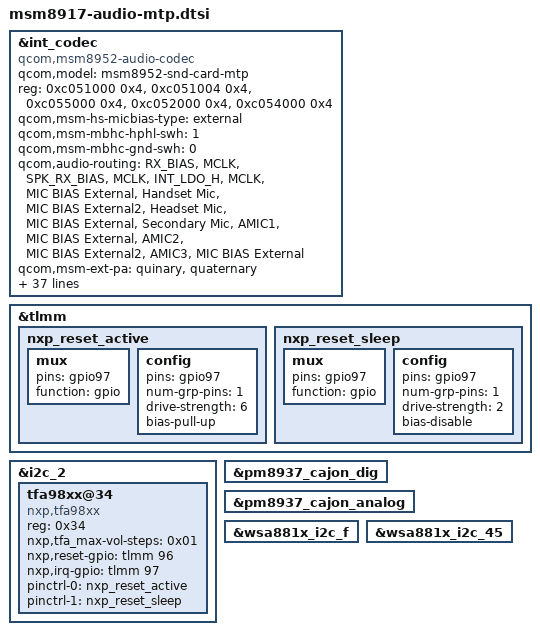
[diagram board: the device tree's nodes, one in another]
/*
 * Copyright (c) 2015-2016, The Linux Foundation. All rights reserved.
 *
 * This program is free software; you can redistribute it and/or modify
 * it under the terms of the GNU General Public License version 2 and
 * only version 2 as published by the Free Software Foundation.
 *
 * This program is distributed in the hope that it will be useful,
 * but WITHOUT ANY WARRANTY; without even the implied warranty of
 * MERCHANTABILITY or FITNESS FOR A PARTICULAR PURPOSE.  See the
 * GNU General Public License for more details.
 */

&int_codec {
	status = "ok";
	/delete-property/ qcom,cdc-us-euro-gpios;
	compatible = "qcom,msm8952-audio-codec";
	qcom,model = "msm8952-snd-card-mtp";
	
	reg =   <0xc051000 0x4>,
		<0xc051004 0x4>,
		<0xc055000 0x4>,
		<0xc052000 0x4>,
		<0xc054000 0x4>;
	reg-names = "csr_gp_io_mux_mic_ctl",
		"csr_gp_io_mux_spkr_ctl",
		"csr_gp_io_lpaif_pri_pcm_pri_mode_muxsel",
		"csr_gp_io_mux_quin_ctl",
		"csr_gp_io_mux_mic_ext_clk_ctl";

	qcom,msm-hs-micbias-type = "external";
	qcom,msm-mbhc-hphl-swh = <1>;
	qcom,msm-mbhc-gnd-swh = <0>;  

	qcom,audio-routing =
		"RX_BIAS", "MCLK",
		"SPK_RX_BIAS", "MCLK",
		"INT_LDO_H", "MCLK",
		"MIC BIAS External", "Handset Mic",
		"MIC BIAS External2", "Headset Mic",
		"MIC BIAS External", "Secondary Mic",
		"AMIC1", "MIC BIAS External",
		"AMIC2", "MIC BIAS External2",
 		"AMIC3", "MIC BIAS External";   


	qcom,msm-ext-pa = "quinary","quaternary";
	qcom,msm-mclk-freq = <9600000>;
	qcom,msm-gpios =    "pri_i2s",
			"quin_i2s";
	qcom,pinctrl-names = 
		"all_off", 
		"pri_i2s_act",
		"quin_act",
		"quin_pri_i2s_act";
	pinctrl-names = 
		"all_off", 
		"pri_i2s_act",
		"quin_act",
		"quin_pri_i2s_act";

	qcom,hdmi-dba-codec-rx;


		asoc-platform = <&pcm0>, <&pcm1>, <&pcm2>, <&voip>, <&voice>,
		<&loopback>, <&compress>, <&hostless>,
		<&afe>, <&lsm>, <&routing>, <&lpa>;
	asoc-platform-names = "msm-pcm-dsp.0", "msm-pcm-dsp.1",
		"msm-pcm-dsp.2", "msm-voip-dsp",
		"msm-pcm-voice", "msm-pcm-loopback",
		"msm-compress-dsp", "msm-pcm-hostless",
		"msm-pcm-afe", "msm-lsm-client",
		"msm-pcm-routing", "msm-pcm-lpa";
	asoc-cpu = <&dai_pri_auxpcm>,
	<&dai_mi2s0>, <&dai_mi2s1>,
	<&dai_mi2s2>, <&dai_mi2s3>,
	<&dai_mi2s5>, <&dai_mi2s6>,
	<&sb_0_rx>, <&sb_0_tx>, <&sb_1_rx>, <&sb_1_tx>,
	<&sb_3_rx>, <&sb_3_tx>, <&sb_4_rx>, <&sb_4_tx>,
	<&bt_sco_rx>, <&bt_sco_tx>,
	<&int_fm_rx>, <&int_fm_tx>,
	<&afe_pcm_rx>, <&afe_pcm_tx>,
	<&afe_proxy_rx>, <&afe_proxy_tx>,
	<&incall_record_rx>, <&incall_record_tx>,
	<&incall_music_rx>, <&incall_music_2_rx>;
	asoc-cpu-names = "msm-dai-q6-auxpcm.1",
		"msm-dai-q6-mi2s.0", "msm-dai-q6-mi2s.1",
		"msm-dai-q6-mi2s.2", "msm-dai-q6-mi2s.3",
		"msm-dai-q6-mi2s.5", "msm-dai-q6-mi2s.6",
		"msm-dai-q6-dev.16384", "msm-dai-q6-dev.16385",
		"msm-dai-q6-dev.16386", "msm-dai-q6-dev.16387",
		"msm-dai-q6-dev.16390", "msm-dai-q6-dev.16391",
		"msm-dai-q6-dev.16392", "msm-dai-q6-dev.16393",
		"msm-dai-q6-dev.12288", "msm-dai-q6-dev.12289",
		"msm-dai-q6-dev.12292", "msm-dai-q6-dev.12293",
		"msm-dai-q6-dev.224", "msm-dai-q6-dev.225",
		"msm-dai-q6-dev.241", "msm-dai-q6-dev.240",
		"msm-dai-q6-dev.32771", "msm-dai-q6-dev.32772",
		"msm-dai-q6-dev.32773", "msm-dai-q6-dev.32770";
};

&tlmm
{
	nxp_reset_active: nxp_reset_active {
		mux {
			pins = "gpio97";
			function =  "gpio";
		};
		config {
			pins = "gpio97";
			num-grp-pins = <1>;
			drive-strength = <6>;
			bias-pull-up;
		};
	};

	nxp_reset_sleep: nxp_reset_sleep {
			mux {
				pins = "gpio97";
				function =  "gpio";
			};
			config {
				pins = "gpio97";
				num-grp-pins = <1>;
				drive-strength = <2>;
				bias-disable;
			};
	};
};

&i2c_2 {
	tfa98xx@34 {
		compatible = "nxp,tfa98xx";
		reg = <0x34>;
		nxp,tfa_max-vol-steps=<0x01>;
		nxp,reset-gpio = <&tlmm 96 0>;
		nxp,irq-gpio = <&tlmm 97 0x2008>;
		pinctrl-names = "nxp_reset_active","nxp_reset_suspend";
		pinctrl-0 = <&nxp_reset_active>;
		pinctrl-1 = <&nxp_reset_sleep>;
		status = "okay";
		};
};

&pm8937_cajon_dig {
	status = "okay";
};

&pm8937_cajon_analog {
	status = "okay";
};

&wsa881x_i2c_f {
	status = "okay";
};

&wsa881x_i2c_45 {
	status = "okay";
};
